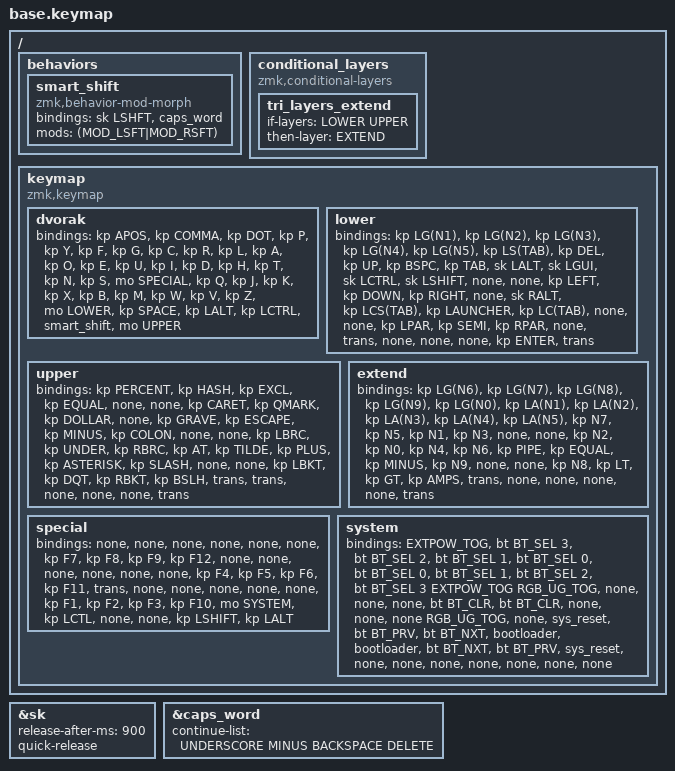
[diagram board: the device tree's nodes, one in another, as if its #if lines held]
/*
 * Copyright (c) 2024 Charly Delay <0xcharly>
 *
 * SPDX-License-Identifier: MIT
 */

#include <behaviors.dtsi>
#include <behaviors/num_word.dtsi> // requires auto-layer module
#include <dt-bindings/zmk/keys.h>
#include <dt-bindings/zmk/ext_power.h>
#include <dt-bindings/zmk/keys.h>
#include <dt-bindings/zmk/rgb.h>

#ifdef CONFIG_WIRELESS
    #include <dt-bindings/zmk/bt.h>
#endif

// Layers & HRM config.
#define DVORAK 0
#define LOWER 1
#define UPPER 2
#define EXTEND 3
#define SPECIAL 4
#define SYSTEM 5

// Custom keycodes.
#define LAUNCHER (LG(SPACE))
#define LCS(kp) (LC(LS(kp)))

#define EXTPOW_TOG &ext_power EXT_POWER_TOGGLE_CMD
#define RGB_UG_TOG &rgb_ug RGB_TOG

// Adjust sticky-keys configuration.
&sk {
    release-after-ms = <900>;  // Release after 0.9s.
    quick-release;             // No double capitalization when rolling keys.
};

// Adjust Caps Word configuration.
&caps_word {
  continue-list = <UNDERSCORE MINUS BACKSPACE DELETE>;
};

// Custom behaviors.
/ {
  behaviors {
    // tap: sticky-shift | shift + tap/ double-tap: caps-word | hold: nav layer.
    smart_shift: smart_shift {
      compatible = "zmk,behavior-mod-morph";
      #binding-cells = <0>;
      bindings = <&sk LSHFT>, <&caps_word>;
      mods = <(MOD_LSFT|MOD_RSFT)>;
    };
  };
};

// Tri-layers.
/ {
  conditional_layers {
    // LOWER + UPPER -> EXTEND
    compatible = "zmk,conditional-layers";
    tri_layers_extend {
      if-layers = <LOWER UPPER>;
      then-layer = <EXTEND>;
    };
  };
};

// Layout.
/ {
  // 34-key keymap, using a Dvorak base layer.
  keymap {
    compatible = "zmk,keymap";

    // Traditional Dvorak layout.
    dvorak {
      bindings = <
   // ╭──────────────────────────────────────────────────────────────────╮ ╭──────────────────────────────────────────────────────────────────╮
        &kp APOS     &kp COMMA    &kp DOT      &kp P        &kp Y            &kp F        &kp G        &kp C        &kp R        &kp L
        &kp A        &kp O        &kp E        &kp U        &kp I            &kp D        &kp H        &kp T        &kp N        &kp S
        &mo SPECIAL  &kp Q        &kp J        &kp K        &kp X            &kp B        &kp M        &kp W        &kp V        &kp Z
   // ╰──────────────────────────────────────────────────────────────────┤ ├──────────────────────────────────────────────────────────────────╯
#ifdef CONFIG_36_KEYS
                                  &mo LOWER    &kp SPACE    &kp LALT         &kp LCTRL    &smart_shift &mo UPPER
#else
                                  &mo LOWER    &kp SPACE                                  &smart_shift &mo UPPER
#endif // CONFIG_36_KEYS
   //                                        ╰───────────────────────────╯ ╰───────────────────────────╯
      >;
    };

    /**
     * Lower layer. Left thumb down.
     *
     * Symbols.
     *
     *   - Primary hand (left):
     *     - Home-row sticky mods.
     *     - Desktop navigation.
     *   - Secondary hand (right):
     *     - Tab, Shift-Tab, backspace, delete.
     *     - Inverted T arrow cluster.
     *     - Semi-colon for synergy with parenthesis.
     */
    lower {
      bindings = <
   // ╭──────────────────────────────────────────────────────────────────╮ ╭──────────────────────────────────────────────────────────────────╮
        &kp LG(N1)   &kp LG(N2)   &kp LG(N3)   &kp LG(N4)   &kp LG(N5)       &kp LS(TAB)  &kp DEL      &kp UP       &kp BSPC     &kp TAB
        &sk LALT     &sk LGUI     &sk LCTRL    &sk LSHIFT   &none            &none        &kp LEFT     &kp DOWN     &kp RIGHT    &none
        &sk RALT     &kp LCS(TAB) &kp LAUNCHER &kp LC(TAB)  &none            &none        &kp LPAR     &kp SEMI     &kp RPAR     &none
   // ╰──────────────────────────────────────────────────────────────────┤ ├──────────────────────────────────────────────────────────────────╯
#ifdef CONFIG_36_KEYS
                                  &trans /*↓*/ &none        &none            &none        &kp ENTER    &trans
#else
                                  &trans /*↓*/ &none                                      &kp ENTER    &trans
#endif // CONFIG_36_KEYS
   //                                        ╰───────────────────────────╯ ╰───────────────────────────╯
      >;
    };

    /**
     * Upper layer. Right thumb down.
     *
     * Symbols.
     *
     *   - Primary hand (right):
     *     - Underscore for symmetry with dash on other half.
     *     - Caret and dollar for Vi-motions.
     *     - Square and curly brackets.
     *     - Double quotes for modal editors registry.
     *   - Secondary hand (left):
     *     - Most common operators.
     */
    upper {
      bindings = <
   // ╭──────────────────────────────────────────────────────────────────╮ ╭──────────────────────────────────────────────────────────────────╮
        &kp PERCENT  &kp HASH     &kp EXCL     &kp EQUAL    &none            &none        &kp CARET    &kp QMARK    &kp DOLLAR   &none
        &kp GRAVE    &kp ESCAPE   &kp MINUS    &kp COLON    &none            &none        &kp LBRC     &kp UNDER    &kp RBRC     &kp AT
        &kp TILDE    &kp PLUS     &kp ASTERISK &kp SLASH    &none            &none        &kp LBKT     &kp DQT      &kp RBKT     &kp BSLH
   // ╰──────────────────────────────────────────────────────────────────┤ ├──────────────────────────────────────────────────────────────────╯
#ifdef CONFIG_36_KEYS
                                  &trans       &trans       &none            &none        &none        &trans /*↓*/
#else
                                  &trans       &trans                                     &none        &trans /*↓*/
#endif // CONFIG_36_KEYS
   //                                        ╰───────────────────────────╯ ╰───────────────────────────╯
      >;
    };

    /**
     * Extend layer. Classic tri-layer activated from both lower and upper layers.
     *
     * Numbers and some symbols.
     *
     *   - Optimized numrow.
     *   - Base-layer symbols so that every symbol is accessible by moving at most one finger.
     */
    extend {
      bindings = <
   // ╭──────────────────────────────────────────────────────────────────╮ ╭──────────────────────────────────────────────────────────────────╮
        &kp LG(N6)   &kp LG(N7)   &kp LG(N8)   &kp LG(N9)   &kp LG(N0)       &kp LA(N1)   &kp LA(N2)   &kp LA(N3)   &kp LA(N4)   &kp LA(N5)
        &kp N7       &kp N5       &kp N1       &kp N3       &none            &none        &kp N2       &kp N0       &kp N4       &kp N6
        &kp PIPE     &kp EQUAL    &kp MINUS    &kp N9       &none            &none        &kp N8       &kp LT       &kp GT       &kp AMPS
   // ╰──────────────────────────────────────────────────────────────────┤ ├──────────────────────────────────────────────────────────────────╯
#ifdef CONFIG_36_KEYS
                                  &trans /*↓*/ &none        &none            &none        &none        &trans /*↓*/
#else
                                  &trans /*↓*/ &none                                      &none        &trans /*↓*/
#endif // CONFIG_36_KEYS
   //                                        ╰───────────────────────────╯ ╰───────────────────────────╯
      >;
    };

    /**
     * F-row layer.
     *
     * More desktop shortcuts and navigation, and lesser used keys.
     *
     *   - F-keys.
     */
    special {
      bindings = <
   // ╭──────────────────────────────────────────────────────────────────╮ ╭──────────────────────────────────────────────────────────────────╮
        &none        &none        &none        &none        &none            &none        &kp F7       &kp F8       &kp F9       &kp F12
        &none        &none        &none        &none        &none            &none        &kp F4       &kp F5       &kp F6       &kp F11
        &trans /*↓*/ &none        &none        &none        &none            &none        &kp F1       &kp F2       &kp F3       &kp F10
   // ╰──────────────────────────────────────────────────────────────────┤ ├──────────────────────────────────────────────────────────────────╯
#ifdef CONFIG_36_KEYS
                                  &mo SYSTEM   &kp LCTL     &none            &none        &kp LSHIFT   &kp LALT
#else
                                  &none        &kp LCTL                                   &kp LSHIFT   &kp LALT
#endif // CONFIG_36_KEYS
   //                                        ╰───────────────────────────╯ ╰───────────────────────────╯
      >;
    };

   /**
    * System layer for hardware controls.
    *
    *   - Bluetooth channels (if wireless).
    *   - Reset/bootloader.
    *   - Ext power/RGB.
    */
    system {
      bindings = <
   // ╭──────────────────────────────────────────────────────────────────╮ ╭──────────────────────────────────────────────────────────────────╮
#ifdef CONFIG_WIRELESS
        EXTPOW_TOG   &bt BT_SEL 3 &bt BT_SEL 2 &bt BT_SEL 1 &bt BT_SEL 0     &bt BT_SEL 0 &bt BT_SEL 1 &bt BT_SEL 2 &bt BT_SEL 3 EXTPOW_TOG
        RGB_UG_TOG   &none        &none        &none        &bt BT_CLR       &bt BT_CLR   &none        &none        &none        RGB_UG_TOG
        &none        &sys_reset   &bt BT_PRV   &bt BT_NXT   &bootloader      &bootloader  &bt BT_NXT   &bt BT_PRV   &sys_reset   &none
#else
        EXTPOW_TOG   &none        &none        &none        &none            &none        &none        &none        &none        EXTPOW_TOG
        RGB_UG_TOG   &none        &none        &none        &none            &none        &none        &none        &none        RGB_UG_TOG
        &none        &sys_reset   &none        &none        &bootloader      &bootloader  &none        &none        &sys_reset   &none
#endif  // CONFIG_WIRELESS
   // ╰──────────────────────────────────────────────────────────────────┤ ├──────────────────────────────────────────────────────────────────╯
#ifdef CONFIG_36_KEYS
                                  &none        &none        &none            &none        &none        &none
#else
                                  &none        &none                                      &none        &none
#endif // CONFIG_36_KEYS
   //                                        ╰───────────────────────────╯ ╰───────────────────────────╯
      >;
    };
  };
};
